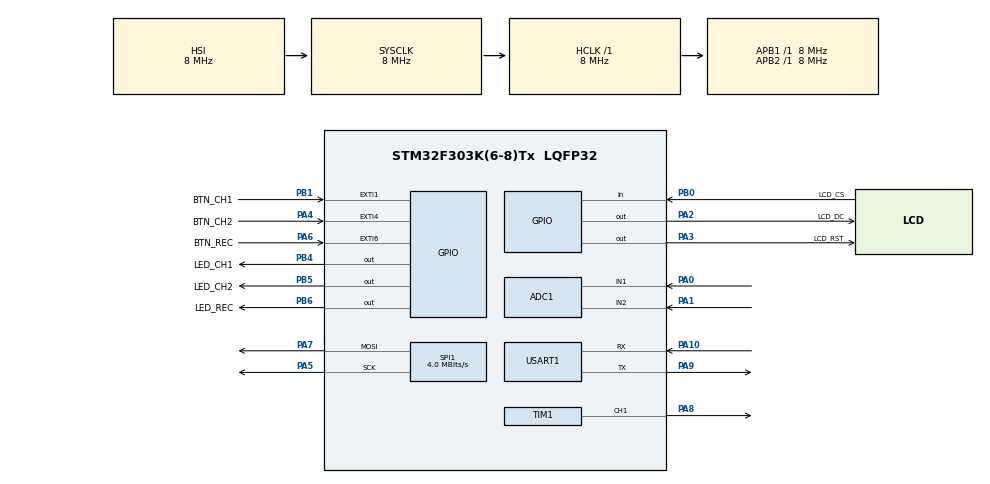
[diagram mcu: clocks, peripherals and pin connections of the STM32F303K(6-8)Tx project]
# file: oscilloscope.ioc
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ADC1.Channel-0\#ChannelRegularConversion=ADC_CHANNEL_1
ADC1.NbrOfConversionFlag=1
ADC1.Offset-0\#ChannelRegularConversion=0
ADC1.OffsetNumber-0\#ChannelRegularConversion=ADC_OFFSET_NONE
ADC1.Rank-0\#ChannelRegularConversion=1
ADC1.SamplingTime-0\#ChannelRegularConversion=ADC_SAMPLETIME_1CYCLE_5
ADC1.SubFamily=STM32F303x8
ADC1.master=1
Mcu.Family=STM32F3
Mcu.Name=STM32F303K(6-8)Tx
Mcu.Package=LQFP32
NVIC.EXTI1_IRQn=true\:0\:0\:false\:false\:true\:true\:true\:true
NVIC.EXTI4_IRQn=true\:0\:0\:false\:false\:true\:true\:true\:true
NVIC.EXTI9_5_IRQn=true\:0\:0\:false\:false\:true\:true\:true\:true
NVIC.PriorityGroup=NVIC_PRIORITYGROUP_4
PA0.Mode=IN1-Single-Ended
PA0.Signal=ADC1_IN1
PA1.Mode=IN2-Single-Ended
PA1.Signal=ADC1_IN2
PA10.Mode=Asynchronous
PA10.Signal=USART1_RX
PA13.Mode=Serial_Wire
PA13.Signal=SYS_JTMS-SWDIO
PA14.Mode=Serial_Wire
PA14.Signal=SYS_JTCK-SWCLK
PA2.GPIO_Label=LCD_DC
PA2.Signal=GPIO_Output
PA3.GPIO_Label=LCD_RST
PA3.Signal=GPIO_Output
PA4.GPIO_Label=BTN_CH2
PA4.Signal=GPXTI4
PA5.Mode=TX_Only_Simplex_Unidirect_Master
PA5.Signal=SPI1_SCK
PA6.GPIO_Label=BTN_REC
PA6.Signal=GPXTI6
PA7.Mode=TX_Only_Simplex_Unidirect_Master
PA7.Signal=SPI1_MOSI
PA8.Signal=S_TIM1_CH1
PA9.Mode=Asynchronous
PA9.Signal=USART1_TX
PB0.GPIO_Label=LCD_CS
PB0.Signal=GPIO_Input
PB1.GPIO_Label=BTN_CH1
PB1.Signal=GPXTI1
PB4.GPIO_Label=LED_CH1
PB4.Signal=GPIO_Output
PB5.GPIO_Label=LED_CH2
PB5.Signal=GPIO_Output
PB6.GPIO_Label=LED_REC
PB6.Signal=GPIO_Output
ProjectManager.HeapSize=0x200
ProjectManager.StackSize=0x400
ProjectManager.TargetToolchain=Makefile
RCC.AHBFreq_Value=8000000
RCC.APB1Freq_Value=8000000
RCC.APB2Freq_Value=8000000
RCC.CortexFreq_Value=8000000
RCC.HSE_VALUE=8000000
RCC.HSI_VALUE=8000000
RCC.PLLMUL=RCC_PLL_MUL4
RCC.SYSCLKFreq_VALUE=8000000
SH.S_TIM1_CH1.0=TIM1_CH1,PWM Generation1 CH1
SPI1.CalculateBaudRate=4.0 MBits/s
SPI1.Direction=SPI_DIRECTION_2LINES
SPI1.Mode=SPI_MODE_MASTER
SPI1.VirtualType=VM_MASTER
TIM1.Channel-PWM\ Generation1\ CH1=TIM_CHANNEL_1
TIM1.Period=1000
TIM1.Prescaler=64
TIM1.Pulse-PWM\ Generation1\ CH1=500
USART1.VirtualMode-Asynchronous=VM_ASYNC
board=custom

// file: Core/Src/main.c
/* USER CODE BEGIN Header */
/**
  ******************************************************************************
  * @file           : main.c
  * @brief          : Main program body
  ******************************************************************************
  * @attention
  *
  * Copyright (c) 2026 STMicroelectronics.
  * All rights reserved.
  *
  * This software is licensed under terms that can be found in the LICENSE file
  * in the root directory of this software component.
  * If no LICENSE file comes with this software, it is provided AS-IS.
  *
  ******************************************************************************
  */
/* USER CODE END Header */
#include "main.h"

ADC_HandleTypeDef hadc1;

SPI_HandleTypeDef hspi1;

TIM_HandleTypeDef htim1;

UART_HandleTypeDef huart1;

/* USER CODE BEGIN PV */
ADC_ChannelConfTypeDef sConfig = {0};
/* USER CODE END PV */

void SystemClock_Config(void);
static void MX_GPIO_Init(void);
static void MX_ADC1_Init(void);
static void MX_SPI1_Init(void);
static void MX_USART1_UART_Init(void);
static void MX_TIM1_Init(void);

int main(void)
{

  /* MCU Configuration--------------------------------------------------------*/

  /* Reset of all peripherals, Initializes the Flash interface and the Systick. */
  HAL_Init();

  /* Configure the system clock */
  SystemClock_Config();

  /* Initialize all configured peripherals */
  MX_GPIO_Init();
  MX_ADC1_Init();
  MX_SPI1_Init();
  MX_USART1_UART_Init();
  MX_TIM1_Init();
  /* USER CODE BEGIN 2 */
  init();

  draw_rectangle(0, 127, 0, 159, black);
  HAL_TIM_PWM_Start(&htim1, TIM_CHANNEL_1);

  // configure LEDs
  if(source == 0){
    HAL_GPIO_WritePin(LED_CH1_GPIO_Port, LED_CH1_Pin, GPIO_PIN_SET);
  }
  else if(source == 1){
    HAL_GPIO_WritePin(LED_CH2_GPIO_Port, LED_CH2_Pin, GPIO_PIN_SET);
  }

  // Display Axis
  draw_axis(white);

  /* USER CODE END 2 */

  /* Infinite loop */
  /* USER CODE BEGIN WHILE */

  while (1)
  {
    if(source == 1){
      display_PWM_signal(red);
    }
    if (source == 0){
      display_constant_signal(red);
    }
    /* USER CODE END WHILE */

  }
}

void SystemClock_Config(void)
{
  RCC_OscInitTypeDef RCC_OscInitStruct = {0};
  RCC_ClkInitTypeDef RCC_ClkInitStruct = {0};
  RCC_PeriphCLKInitTypeDef PeriphClkInit = {0};

  /** Initializes the RCC Oscillators according to the specified parameters
  * in the RCC_OscInitTypeDef structure.
  */
  RCC_OscInitStruct.OscillatorType = RCC_OSCILLATORTYPE_HSI;
  RCC_OscInitStruct.HSIState = RCC_HSI_ON;
  RCC_OscInitStruct.HSICalibrationValue = RCC_HSICALIBRATION_DEFAULT;
  RCC_OscInitStruct.PLL.PLLState = RCC_PLL_ON;
  RCC_OscInitStruct.PLL.PLLSource = RCC_PLLSOURCE_HSI;
  RCC_OscInitStruct.PLL.PLLMUL = RCC_PLL_MUL4;
  if (HAL_RCC_OscConfig(&RCC_OscInitStruct) != HAL_OK)
  {
    Error_Handler();
  }

  /** Initializes the CPU, AHB and APB buses clocks
  */
  RCC_ClkInitStruct.ClockType = RCC_CLOCKTYPE_HCLK|RCC_CLOCKTYPE_SYSCLK
                              |RCC_CLOCKTYPE_PCLK1|RCC_CLOCKTYPE_PCLK2;
  RCC_ClkInitStruct.SYSCLKSource = RCC_SYSCLKSOURCE_HSI;
  RCC_ClkInitStruct.AHBCLKDivider = RCC_SYSCLK_DIV1;
  RCC_ClkInitStruct.APB1CLKDivider = RCC_HCLK_DIV1;
  RCC_ClkInitStruct.APB2CLKDivider = RCC_HCLK_DIV1;

  if (HAL_RCC_ClockConfig(&RCC_ClkInitStruct, FLASH_LATENCY_0) != HAL_OK)
  {
    Error_Handler();
  }
  PeriphClkInit.PeriphClockSelection = RCC_PERIPHCLK_USART1|RCC_PERIPHCLK_TIM1
                              |RCC_PERIPHCLK_ADC12;
  PeriphClkInit.Usart1ClockSelection = RCC_USART1CLKSOURCE_PCLK1;
  PeriphClkInit.Adc12ClockSelection = RCC_ADC12PLLCLK_DIV1;
  PeriphClkInit.Tim1ClockSelection = RCC_TIM1CLK_HCLK;
  if (HAL_RCCEx_PeriphCLKConfig(&PeriphClkInit) != HAL_OK)
  {
    Error_Handler();
  }
}

static void MX_ADC1_Init(void)
{

  ADC_MultiModeTypeDef multimode = {0};

  /** Common config
  */
  hadc1.Instance = ADC1;
  hadc1.Init.ClockPrescaler = ADC_CLOCK_ASYNC_DIV1;
  hadc1.Init.Resolution = ADC_RESOLUTION_12B;
  hadc1.Init.ScanConvMode = ADC_SCAN_DISABLE;
  hadc1.Init.ContinuousConvMode = DISABLE;
  hadc1.Init.DiscontinuousConvMode = DISABLE;
  hadc1.Init.ExternalTrigConvEdge = ADC_EXTERNALTRIGCONVEDGE_NONE;
  hadc1.Init.ExternalTrigConv = ADC_SOFTWARE_START;
  hadc1.Init.DataAlign = ADC_DATAALIGN_RIGHT;
  hadc1.Init.NbrOfConversion = 1;
  hadc1.Init.DMAContinuousRequests = DISABLE;
  hadc1.Init.EOCSelection = ADC_EOC_SINGLE_CONV;
  hadc1.Init.LowPowerAutoWait = DISABLE;
  hadc1.Init.Overrun = ADC_OVR_DATA_OVERWRITTEN;
  if (HAL_ADC_Init(&hadc1) != HAL_OK)
  {
    Error_Handler();
  }

  /** Configure the ADC multi-mode
  */
  multimode.Mode = ADC_MODE_INDEPENDENT;
  if (HAL_ADCEx_MultiModeConfigChannel(&hadc1, &multimode) != HAL_OK)
  {
    Error_Handler();
  }

  /** Configure Regular Channel
  */
  sConfig.Channel = ADC_CHANNEL_1;
  sConfig.Rank = ADC_REGULAR_RANK_1;
  sConfig.SingleDiff = ADC_SINGLE_ENDED;
  sConfig.SamplingTime = ADC_SAMPLETIME_1CYCLE_5;
  sConfig.OffsetNumber = ADC_OFFSET_NONE;
  sConfig.Offset = 0;
  if (HAL_ADC_ConfigChannel(&hadc1, &sConfig) != HAL_OK)
  {
    Error_Handler();
  }

}

static void MX_SPI1_Init(void)
{

  /* SPI1 parameter configuration*/
  hspi1.Instance = SPI1;
  hspi1.Init.Mode = SPI_MODE_MASTER;
  hspi1.Init.Direction = SPI_DIRECTION_2LINES;
  hspi1.Init.DataSize = SPI_DATASIZE_8BIT;
  hspi1.Init.CLKPolarity = SPI_POLARITY_LOW;
  hspi1.Init.CLKPhase = SPI_PHASE_1EDGE;
  hspi1.Init.NSS = SPI_NSS_SOFT;
  hspi1.Init.BaudRatePrescaler = SPI_BAUDRATEPRESCALER_4;
  hspi1.Init.FirstBit = SPI_FIRSTBIT_MSB;
  hspi1.Init.TIMode = SPI_TIMODE_DISABLE;
  hspi1.Init.CRCCalculation = SPI_CRCCALCULATION_DISABLE;
  hspi1.Init.CRCPolynomial = 7;
  hspi1.Init.CRCLength = SPI_CRC_LENGTH_DATASIZE;
  hspi1.Init.NSSPMode = SPI_NSS_PULSE_ENABLE;
  if (HAL_SPI_Init(&hspi1) != HAL_OK)
  {
    Error_Handler();
  }

}

static void MX_TIM1_Init(void)
{

  TIM_MasterConfigTypeDef sMasterConfig = {0};
  TIM_OC_InitTypeDef sConfigOC = {0};
  TIM_BreakDeadTimeConfigTypeDef sBreakDeadTimeConfig = {0};

  htim1.Instance = TIM1;
  htim1.Init.Prescaler = 64;
  htim1.Init.CounterMode = TIM_COUNTERMODE_UP;
  htim1.Init.Period = 65535;
  htim1.Init.ClockDivision = TIM_CLOCKDIVISION_DIV1;
  htim1.Init.RepetitionCounter = 0;
  htim1.Init.AutoReloadPreload = TIM_AUTORELOAD_PRELOAD_DISABLE;
  if (HAL_TIM_PWM_Init(&htim1) != HAL_OK)
  {
    Error_Handler();
  }
  sMasterConfig.MasterOutputTrigger = TIM_TRGO_RESET;
  sMasterConfig.MasterOutputTrigger2 = TIM_TRGO2_RESET;
  sMasterConfig.MasterSlaveMode = TIM_MASTERSLAVEMODE_DISABLE;
  if (HAL_TIMEx_MasterConfigSynchronization(&htim1, &sMasterConfig) != HAL_OK)
  {
    Error_Handler();
  }
  sConfigOC.OCMode = TIM_OCMODE_PWM1;
  sConfigOC.Pulse = 32768;
  sConfigOC.OCPolarity = TIM_OCPOLARITY_HIGH;
  sConfigOC.OCNPolarity = TIM_OCNPOLARITY_HIGH;
  sConfigOC.OCFastMode = TIM_OCFAST_DISABLE;
  sConfigOC.OCIdleState = TIM_OCIDLESTATE_RESET;
  sConfigOC.OCNIdleState = TIM_OCNIDLESTATE_RESET;
  if (HAL_TIM_PWM_ConfigChannel(&htim1, &sConfigOC, TIM_CHANNEL_1) != HAL_OK)
  {
    Error_Handler();
  }
  sBreakDeadTimeConfig.OffStateRunMode = TIM_OSSR_DISABLE;
  sBreakDeadTimeConfig.OffStateIDLEMode = TIM_OSSI_DISABLE;
  sBreakDeadTimeConfig.LockLevel = TIM_LOCKLEVEL_OFF;
  sBreakDeadTimeConfig.DeadTime = 0;
  sBreakDeadTimeConfig.BreakState = TIM_BREAK_DISABLE;
  sBreakDeadTimeConfig.BreakPolarity = TIM_BREAKPOLARITY_HIGH;
  sBreakDeadTimeConfig.BreakFilter = 0;
  sBreakDeadTimeConfig.Break2State = TIM_BREAK2_DISABLE;
  sBreakDeadTimeConfig.Break2Polarity = TIM_BREAK2POLARITY_HIGH;
  sBreakDeadTimeConfig.Break2Filter = 0;
  sBreakDeadTimeConfig.AutomaticOutput = TIM_AUTOMATICOUTPUT_DISABLE;
  if (HAL_TIMEx_ConfigBreakDeadTime(&htim1, &sBreakDeadTimeConfig) != HAL_OK)
  {
    Error_Handler();
  }
  HAL_TIM_MspPostInit(&htim1);

}

static void MX_USART1_UART_Init(void)
{

  huart1.Instance = USART1;
  huart1.Init.BaudRate = 38400;
  huart1.Init.WordLength = UART_WORDLENGTH_8B;
  huart1.Init.StopBits = UART_STOPBITS_1;
  huart1.Init.Parity = UART_PARITY_NONE;
  huart1.Init.Mode = UART_MODE_TX_RX;
  huart1.Init.HwFlowCtl = UART_HWCONTROL_NONE;
  huart1.Init.OverSampling = UART_OVERSAMPLING_16;
  huart1.Init.OneBitSampling = UART_ONE_BIT_SAMPLE_DISABLE;
  huart1.AdvancedInit.AdvFeatureInit = UART_ADVFEATURE_NO_INIT;
  if (HAL_UART_Init(&huart1) != HAL_OK)
  {
    Error_Handler();
  }

}

static void MX_GPIO_Init(void)
{
  GPIO_InitTypeDef GPIO_InitStruct = {0};

  /* GPIO Ports Clock Enable */
  __HAL_RCC_GPIOA_CLK_ENABLE();
  __HAL_RCC_GPIOB_CLK_ENABLE();

  /*Configure GPIO pin Output Level */
  HAL_GPIO_WritePin(GPIOA, LCD_DC_Pin|LCD_RST_Pin, GPIO_PIN_RESET);

  /*Configure GPIO pin Output Level */
  HAL_GPIO_WritePin(GPIOB, LED_CH1_Pin|LED_CH2_Pin|LED_REC_Pin, GPIO_PIN_RESET);

  /*Configure GPIO pins : LCD_DC_Pin LCD_RST_Pin */
  GPIO_InitStruct.Pin = LCD_DC_Pin|LCD_RST_Pin;
  GPIO_InitStruct.Mode = GPIO_MODE_OUTPUT_PP;
  GPIO_InitStruct.Pull = GPIO_NOPULL;
  GPIO_InitStruct.Speed = GPIO_SPEED_FREQ_LOW;
  HAL_GPIO_Init(GPIOA, &GPIO_InitStruct);

  /*Configure GPIO pins : BTN_CH2_Pin BTN_REC_Pin */
  GPIO_InitStruct.Pin = BTN_CH2_Pin|BTN_REC_Pin;
  GPIO_InitStruct.Mode = GPIO_MODE_IT_RISING;
  GPIO_InitStruct.Pull = GPIO_NOPULL;
  HAL_GPIO_Init(GPIOA, &GPIO_InitStruct);

  /*Configure GPIO pin : LCD_CS_Pin */
  GPIO_InitStruct.Pin = LCD_CS_Pin;
  GPIO_InitStruct.Mode = GPIO_MODE_OUTPUT_PP;
  GPIO_InitStruct.Pull = GPIO_NOPULL;
  HAL_GPIO_Init(LCD_CS_GPIO_Port, &GPIO_InitStruct);

  /*Configure GPIO pin : BTN_CH1_Pin */
  GPIO_InitStruct.Pin = BTN_CH1_Pin;
  GPIO_InitStruct.Mode = GPIO_MODE_IT_RISING;
  GPIO_InitStruct.Pull = GPIO_NOPULL;
  HAL_GPIO_Init(BTN_CH1_GPIO_Port, &GPIO_InitStruct);

  /*Configure GPIO pins : LED_CH1_Pin LED_CH2_Pin LED_REC_Pin */
  GPIO_InitStruct.Pin = LED_CH1_Pin|LED_CH2_Pin|LED_REC_Pin;
  GPIO_InitStruct.Mode = GPIO_MODE_OUTPUT_PP;
  GPIO_InitStruct.Pull = GPIO_NOPULL;
  GPIO_InitStruct.Speed = GPIO_SPEED_FREQ_LOW;
  HAL_GPIO_Init(GPIOB, &GPIO_InitStruct);

  /* EXTI interrupt init*/
  HAL_NVIC_SetPriority(EXTI1_IRQn, 0, 0);
  HAL_NVIC_EnableIRQ(EXTI1_IRQn);

  HAL_NVIC_SetPriority(EXTI4_IRQn, 0, 0);
  HAL_NVIC_EnableIRQ(EXTI4_IRQn);

  HAL_NVIC_SetPriority(EXTI9_5_IRQn, 0, 0);
  HAL_NVIC_EnableIRQ(EXTI9_5_IRQn);

}

void Error_Handler(void)
{
  __disable_irq();
  while (1)
  {
  }
}
